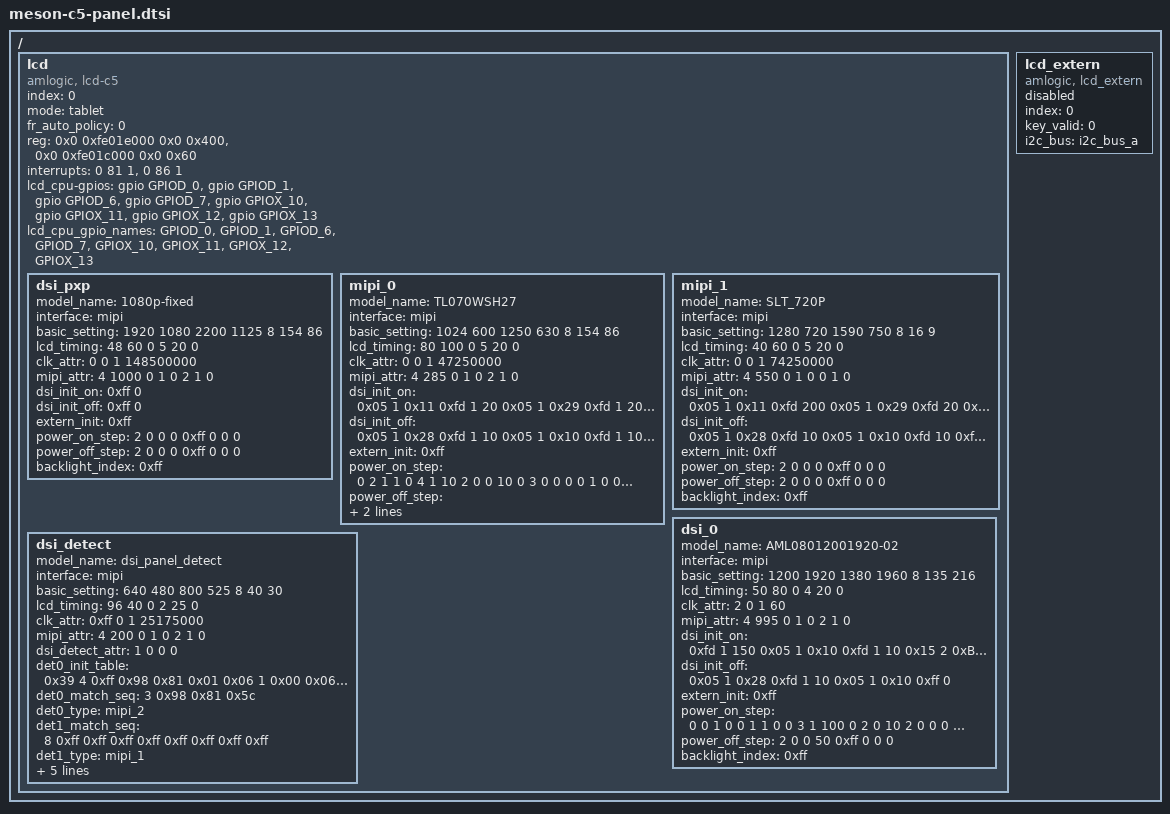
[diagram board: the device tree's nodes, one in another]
// SPDX-License-Identifier: (GPL-2.0+ OR MIT)
/*
 * Copyright (c) 2019 Amlogic, Inc. All rights reserved.
 */

/ {
	lcd:lcd {
		compatible = "amlogic, lcd-c5";
		status = "okay";
		index = <0>;
		mode = "tablet";
		// pxp = <10>;
		fr_auto_policy = <0>; /* 0=disable, 1=enable */
		// clocks = <&clkc CLKID_MIPI_DSI_MEAS>;
		// clock-names = "dsi_meas";
		reg = <0x0 0xfe01e000 0x0 0x400>, <0x0 0xfe01c000 0x0 0x60>; /*dsi host, dsi dphy*/
		interrupts = <0 81 1>, <0 86 1>;
		interrupt-names = "vsync","dsi_intr";
		/* power type:(0=cpu_gpio, 2=signal, 3=extern, 0xff=ending) */
		/* power index:(gpios_index, or extern_index, 0xff=invalid) */
		/* power value:(0=output low, 1=output high, 2=input) */
		/* power delay:(unit in ms) */

		lcd_cpu-gpios = <&gpio GPIOD_0 GPIO_ACTIVE_HIGH>, <&gpio GPIOD_1 GPIO_ACTIVE_HIGH>,
				<&gpio GPIOD_6 GPIO_ACTIVE_HIGH>, <&gpio GPIOD_7 GPIO_ACTIVE_HIGH>,
				<&gpio GPIOX_10 GPIO_ACTIVE_HIGH>,
				<&gpio GPIOX_11 GPIO_ACTIVE_HIGH>,
				<&gpio GPIOX_12 GPIO_ACTIVE_HIGH>,
				<&gpio GPIOX_13 GPIO_ACTIVE_HIGH>;
		lcd_cpu_gpio_names = "GPIOD_0", "GPIOD_1","GPIOD_6","GPIOD_7",
				"GPIOX_10","GPIOX_11","GPIOX_12","GPIOX_13";

		dsi_pxp{
			model_name = "1080p-fixed";
			interface = "mipi";
			basic_setting = <1920 1080 /*h_active, v_active*/
				2200 1125 /*h_period, v_period*/
				8 /*lcd_bits*/
				154 86>; /*screen_widht, screen_height*/
			lcd_timing = <48 60 0 /*hs_width, hs_bp, hs_pol*/
				5 20 0>; /*vs_width, vs_bp, vs_pol*/
			clk_attr = <0 /*fr_adj_type(0=clk, 1=htotal, 2=vtotal)*/
				0 /*clk_ss_level */
				1 /*clk_auto_generate*/
				148500000>; /*pixel_clk(unit in Hz)*/
			mipi_attr = <
				4   /*lane_num*/
				1000 /*bit_rate_max(MHz)*/
				0   /*unused*/
				1   /*operation_mode_init(0=video, 1=command)*/
				0   /*operation_mode_display(0=video, 1=command)*/
				2   /*video_mode_type: 0=sync_pulse,1=sync_event,2=burst)*/
				1   /*clk_always_hs(0=disable,1=enable)*/
				0>; /*unused*/
			/* dsi_init: data_type, num, data... */
			dsi_init_on = <
				0xff 0>; /*ending*/
			dsi_init_off = <
				0xff 0>; /*ending*/
			extern_init = <0xff>; /*0xff for invalid*/

			/* power step: type, index, value, delay(ms) */
			power_on_step = <
				2 0 0 0
				0xff 0 0 0>; /*ending*/
			power_off_step = <
				2 0 0 0
				0xff 0 0 0>; /*ending*/
			backlight_index = <0xff>;
		};

		mipi_0{
			model_name = "TL070WSH27";
			interface = "mipi";
			basic_setting = <1024 600 /*h_active, v_active*/
				1250 630 /*h_period, v_period*/
				8 /*lcd_bits*/
				154 86>; /*screen_widht, screen_height*/
			lcd_timing = <80 100 0 /*hs_width, hs_bp, hs_pol*/
				5 20 0>; /*vs_width, vs_bp, vs_pol*/
			clk_attr = <0 /*fr_adj_type(0=clk, 1=htotal, 2=vtotal)*/
				0 /*clk_ss_level */
				1 /*clk_auto_generate*/
				47250000>; /*pixel_clk(unit in Hz)*/
			mipi_attr = <
				4   /*lane_num*/
				285 /*bit_rate_max(MHz)*/
				0   /*unused*/
				1   /*operation_mode_init(0=video, 1=command)*/
				0   /*operation_mode_display(0=video, 1=command)*/
				2   /*video_mode_type: 0=sync_pulse,1=sync_event,2=burst)*/
				1   /*clk_always_hs(0=disable,1=enable)*/
				0>; /*unused*/
			/* dsi_init: data_type, num, data... */
			dsi_init_on = <
				0x05 1 0x11
				0xfd 1 20 /*delay(ms)*/
				0x05 1 0x29
				0xfd 1 20 /*delay(ms)*/
				0xff 0>; /*ending*/
			dsi_init_off = <0x05 1 0x28
				0xfd 1 10 /*delay(ms)*/
				0x05 1 0x10
				0xfd 1 10 /*delay(ms)*/
				0xff 0>; /*ending*/
			extern_init = <0xff>; /*0xff for invalid*/

			/* power step: type, index, value, delay(ms) */
			power_on_step = <
				0 2 1 1 /* GPIOD_6 3v3 */
				0 4 1 10 /* GPIOX_10 rst */
				2 0 0 10
				0 3 0 0 /* GPIOD_7 bl_pwm */
				0 0 1 0 /* GPIOD_0 bl_en */
				0xff 0 0 0>; /*ending*/
			power_off_step = <
				0 3 1 100 /* GPIOD_7 bl_pwm */
				0 0 0 0 /* GPIOD_0 bl_en */
				2 0 0 10
				0 2 0 0 /* GPIOD_6 3v3 */
				0 4 0 10 /* GPIOX_10 rst */
				0xff 0 0 0>; /*ending*/
			backlight_index = <0xff>;
		};
		mipi_1{
			model_name = "SLT_720P";
			interface = "mipi";
			/*h_active, v_active, h_period, v_period, color_bit, width, height*/
			basic_setting = <1280 720 1590 750 8 16 9>;
			/*hs_width, hs_bp, hs_pol, vs_width, vs_bp, vs_pol*/
			lcd_timing = <40 60 0 5 20 0>;
			clk_attr = <0 0 1 74250000>;
			/* <lane, bit_rate, /, mode_init(0=video,1=cmd), mode_disp(0=video,1=cmd)*/
			/* video_mode(0=sync_pulse,1=sync_event,2=burst), clk_hs, />*/
			mipi_attr = <4 550 0 1 0 0 1 0>;
			dsi_init_on = <
				0x05 1 0x11
				0xfd 200
				0x05 1 0x29
				0xfd 20
				0xff 0xff>; /* ending flag */
			dsi_init_off = <
				0x05 1 0x28
				0xfd 10
				0x05 1 0x10
				0xfd 10
				0xff 0xff>; /* ending flag */
			/* extern_init: 0xff for invalid */
			extern_init = <0xff>;
			/* power step: type,index,value,delay(ms) */
			power_on_step = <
				2 0 0 0
				0xff 0 0 0>;
			power_off_step = <
				2 0 0 0
				0xff 0 0 0>;
			backlight_index = <0xff>;
		};

		dsi_0{
			model_name = "AML08012001920-02";
			interface = "mipi";
			/*h_active, v_active, h_period, v_period, color_bit, width, height*/
			basic_setting = <1200 1920 1380 1960 8 135 216>;
			/*hs_width, hs_bp, hs_pol, vs_width, vs_bp, vs_pol*/
			lcd_timing = <50 80 0 4 20 0>;
			clk_attr = <2 0 1 60>;
			/* <lane, bit_rate, /, mode_init(0=video,1=cmd), mode_disp(0=video,1=cmd)*/
			/* video_mode(0=sync_pulse,1=sync_event,2=burst), clk_hs, />*/
			mipi_attr = <4 995 0 1 0 2 1 0>;
			/* dsi_init: data_type, num, data... */
			dsi_init_on = <
				0xfd 1 150
				0x05 1 0x10
				0xfd 1 10
				0x15 2 0xB0 0x05 0x15 2 0xB3 0x52 0x15 2 0xB0 0x01 0x15 2 0xC8 0x00
				0x15 2 0xC9 0x00 0x15 2 0xCC 0x26 0x15 2 0xCD 0x26 0x15 2 0xDC 0x00
				0x15 2 0xDD 0x00 0x15 2 0xE0 0x26 0x15 2 0xE1 0x26 0x15 2 0xB0 0x03
				0x15 2 0xC3 0x2A 0x15 2 0xE7 0x2A 0x15 2 0xC5 0x2A 0x15 2 0xDE 0x2A
				0x15 2 0xB0 0x00 0x15 2 0xB6 0x03 0x15 2 0xBA 0x87 0x15 2 0xBD 0x78
				0x15 2 0xBF 0x15 0x15 2 0xC0 0x12 0x15 2 0xC2 0x0C 0x15 2 0xC3 0x02
				0x15 2 0xC4 0x0C 0x15 2 0xC5 0x02 0x15 2 0xB0 0x06 0x15 2 0xC0 0xA5
				0x15 2 0xD5 0x20 0x15 2 0xC0 0x00
				0x15 2 0xB0 0x02 /* page2 */
				0x15 2 0xC0 0x00 0x15 2 0xC1 0x02 0x15 2 0xC2 0x06 0x15 2 0xC3 0x16
				0x15 2 0xC4 0x0E 0x15 2 0xC5 0x18 0x15 2 0xC6 0x26 0x15 2 0xC7 0x32
				0x15 2 0xC8 0x3F 0x15 2 0xC9 0x3F 0x15 2 0xCA 0x3F 0x15 2 0xCB 0x3F
				0x15 2 0xCC 0x3D 0x15 2 0xCD 0x2F 0x15 2 0xCE 0x2F 0x15 2 0xCF 0x2F
				0x15 2 0xD0 0x07 0x15 2 0xD2 0x00 0x15 2 0xD3 0x02 0x15 2 0xD4 0x06
				0x15 2 0xD5 0x12 0x15 2 0xD6 0x0A 0x15 2 0xD7 0x14 0x15 2 0xD8 0x22
				0x15 2 0xD9 0x2E 0x15 2 0xDA 0x3D 0x15 2 0xDB 0x3F 0x15 2 0xDC 0x3F
				0x15 2 0xDD 0x3F 0x15 2 0xDE 0x3D 0x15 2 0xDF 0x2F 0x15 2 0xE0 0x2F
				0x15 2 0xE1 0x2F 0x15 2 0xE2 0x07
				0x15 2 0xB0 0x07 /* page7 */
				0x15 2 0xB1 0x00 0x15 2 0xB2 0x19 0x15 2 0xB3 0x31 0x15 2 0xB4 0x5A
				0x15 2 0xB5 0x7C 0x15 2 0xB6 0x9C 0x15 2 0xB7 0xD3 0x15 2 0xB8 0x0E
				0x15 2 0xB9 0x7D 0x15 2 0xBA 0xE0 0x15 2 0xBB 0x7A 0x15 2 0xBC 0xE6
				0x15 2 0xBD 0xE9 0x15 2 0xBE 0x41 0x15 2 0xBF 0x91 0x15 2 0xC0 0xB0
				0x15 2 0xC1 0xCF 0x15 2 0xC2 0xDC 0x15 2 0xC3 0xE9 0x15 2 0xC4 0xEF
				0x15 2 0xC5 0xF5 0x15 2 0xC6 0xFA 0x15 2 0xC7 0xFB 0x15 2 0xC8 0xFC
				0x15 2 0xC9 0x00 0x15 2 0xCA 0x01 0x15 2 0xCB 0x5A 0x15 2 0xCC 0xBF
				0x15 2 0xCD 0xFF 0x15 2 0xCE 0xFF
				0x15 2 0xB0 0x08 /* page8 */
				0x15 2 0xB1 0x00 0x15 2 0xB2 0x19 0x15 2 0xB3 0x31 0x15 2 0xB4 0x5A
				0x15 2 0xB5 0x7C 0x15 2 0xB6 0x9C 0x15 2 0xB7 0xD3 0x15 2 0xB8 0x0E
				0x15 2 0xB9 0x7D 0x15 2 0xBA 0xE0 0x15 2 0xBB 0x7A 0x15 2 0xBC 0xE6
				0x15 2 0xBD 0xE9 0x15 2 0xBE 0x41 0x15 2 0xBF 0x91 0x15 2 0xC0 0xB0
				0x15 2 0xC1 0xCF 0x15 2 0xC2 0xDC 0x15 2 0xC3 0xE9 0x15 2 0xC4 0xEF
				0x15 2 0xC5 0xF5 0x15 2 0xC6 0xFA 0x15 2 0xC7 0xFB 0x15 2 0xC8 0xFC
				0x15 2 0xC9 0x00 0x15 2 0xCA 0x01 0x15 2 0xCB 0x5A 0x15 2 0xCC 0xBF
				0x15 2 0xCD 0xFF 0x15 2 0xCE 0xFF
				0x15 2 0xB0 0x09 /* page9 */
				0x15 2 0xB1 0x00 0x15 2 0xB2 0x19 0x15 2 0xB3 0x31 0x15 2 0xB4 0x5A
				0x15 2 0xB5 0x7C 0x15 2 0xB6 0x9C 0x15 2 0xB7 0xD3 0x15 2 0xB8 0x0E
				0x15 2 0xB9 0x7D 0x15 2 0xBA 0xE0 0x15 2 0xBB 0x7A 0x15 2 0xBC 0xE6
				0x15 2 0xBD 0xE9 0x15 2 0xBE 0x41 0x15 2 0xBF 0x91 0x15 2 0xC0 0xB0
				0x15 2 0xC1 0xCF 0x15 2 0xC2 0xDC 0x15 2 0xC3 0xE9 0x15 2 0xC4 0xEF
				0x15 2 0xC5 0xF5 0x15 2 0xC6 0xFA 0x15 2 0xC7 0xFB 0x15 2 0xC8 0xFC
				0x15 2 0xC9 0x00 0x15 2 0xCA 0x01 0x15 2 0xCB 0x5A 0x15 2 0xCC 0xBF
				0x15 2 0xCD 0xFF 0x15 2 0xCE 0xFF
				0x15 2 0xB0 0x0A /* page10 */
				0x15 2 0xB1 0x00 0x15 2 0xB2 0x19 0x15 2 0xB3 0x31 0x15 2 0xB4 0x5A
				0x15 2 0xB5 0x7C 0x15 2 0xB6 0x9C 0x15 2 0xB7 0xD3 0x15 2 0xB8 0x0E
				0x15 2 0xB9 0x7D 0x15 2 0xBA 0xE0 0x15 2 0xBB 0x7A 0x15 2 0xBC 0xE6
				0x15 2 0xBD 0xE9 0x15 2 0xBE 0x41 0x15 2 0xBF 0x91 0x15 2 0xC0 0xB0
				0x15 2 0xC1 0xCF 0x15 2 0xC2 0xDC 0x15 2 0xC3 0xE9 0x15 2 0xC4 0xEF
				0x15 2 0xC5 0xF5 0x15 2 0xC6 0xFA 0x15 2 0xC7 0xFC 0x15 2 0xC8 0xFC
				0x15 2 0xC9 0x00 0x15 2 0xCA 0x01 0x15 2 0xCB 0x5A 0x15 2 0xCC 0xBF
				0x15 2 0xCD 0xFF 0x15 2 0xCE 0xFF
				0x15 2 0xB0 0x0B /* page11 */
				0x15 2 0xB1 0x00 0x15 2 0xB2 0x19 0x15 2 0xB3 0x31 0x15 2 0xB4 0x5A
				0x15 2 0xB5 0x7C 0x15 2 0xB6 0x9C 0x15 2 0xB7 0xD3 0x15 2 0xB8 0x0E
				0x15 2 0xB9 0x7D 0x15 2 0xBA 0xE0 0x15 2 0xBB 0x7A 0x15 2 0xBC 0xE6
				0x15 2 0xBD 0xE9 0x15 2 0xBE 0x41 0x15 2 0xBF 0x91 0x15 2 0xC0 0xB0
				0x15 2 0xC1 0xCF 0x15 2 0xC2 0xDC 0x15 2 0xC3 0xE9 0x15 2 0xC4 0xEF
				0x15 2 0xC5 0xF5 0x15 2 0xC6 0xFA 0x15 2 0xC7 0xFC 0x15 2 0xC8 0xFC
				0x15 2 0xC9 0x00 0x15 2 0xCA 0x01 0x15 2 0xCB 0x5A 0x15 2 0xCC 0xBF
				0x15 2 0xCD 0xFF 0x15 2 0xCE 0xFF
				0x15 2 0xB0 0x0C /* page12 */
				0x15 2 0xB1 0x00 0x15 2 0xB2 0x19 0x15 2 0xB3 0x31 0x15 2 0xB4 0x5A
				0x15 2 0xB5 0x7C 0x15 2 0xB6 0x9C 0x15 2 0xB7 0xD3 0x15 2 0xB8 0x0E
				0x15 2 0xB9 0x7D 0x15 2 0xBA 0xE0 0x15 2 0xBB 0x7A 0x15 2 0xBC 0xE6
				0x15 2 0xBD 0xE9 0x15 2 0xBE 0x41 0x15 2 0xBF 0x91 0x15 2 0xC0 0xB0
				0x15 2 0xC1 0xCF 0x15 2 0xC2 0xDC 0x15 2 0xC3 0xE9 0x15 2 0xC4 0xEF
				0x15 2 0xC5 0xF5 0x15 2 0xC6 0xFA 0x15 2 0xC7 0xFC 0x15 2 0xC8 0xFC
				0x15 2 0xC9 0x00 0x15 2 0xCA 0x01 0x15 2 0xCB 0x5A 0x15 2 0xCC 0xBF
				0x15 2 0xCD 0xFF 0x15 2 0xCE 0xFF
				0xfd 1 10
				0x05 1 0x11
				0xfd 1 100
				0x05 1 0x29
				0xfd 1 50
				0xff 0>; /*ending*/
			dsi_init_off = <
				0x05 1 0x28
				0xfd 1 10
				0x05 1 0x10
				0xff 0>;
			extern_init = <0xff>; /*0xff for invalid*/

			/* power step: type, index, value, delay(ms) */
			power_on_step = <
				0 0 1 0
				0 1 1 0
				0 3 1 100
				0 2 0 10
				2 0 0 0
				0xff 0 0 0>; /*ending*/
			power_off_step = <
				2 0 0 50
				0xff 0 0 0>; /*ending*/
			backlight_index = <0xff>;
		};

		dsi_detect{
			model_name = "dsi_panel_detect";
			interface = "mipi";

			//<H_active, V_active, H_period, V_period, lcd_bits, width, height>
			basic_setting = <640 480 800 525 8 40 30>;
			//<HSync, HS_backporch, HS_pol, VSync, VS_backporch, VS_pol>
			lcd_timing = <96 40 0 2 25 0>;
			//<fr_adj_type clk_ss clk_auto_generate PixelClk>
			clk_attr = <0xff 0 1 25175000>;
			//<lane_num bit_rate \ mode_init mode_display video_mode clk_always_hs \>
			mipi_attr = <4 200 0 1 0 2 1 0>;

			//<stored2env \ \ \>
			dsi_detect_attr = <1 0 0 0>;
			/* dsi_init: data_type, num, data... */
			det0_init_table = <
				0x39 4 0xff 0x98 0x81 0x01
				0x06 1 0x00 0x06 1 0x01 0x06 1 0x02
				0xff 0>;
			det0_match_seq = <3 0x98 0x81 0x5c>;
			det0_type = "mipi_2";

			det1_match_seq = <8 0xff 0xff 0xff 0xff 0xff 0xff 0xff 0xff>;
			det1_type = "mipi_1";

			fallback_type = "mipi_0";

			/* power step: type, index, value, delay(ms) */
			power_on_step = <
				0 0 1 10 /*vcc en*/
				0 1 1 1 /*rst high*/
				0 3 1 30 /*3v3 high*/
				0 1 0 10 /*rst low*/
				0 1 1 20 /*rst high*/
				2 0 0 0
				0 0 0 1
				0 1 0 1 /*rst low*/
				0 3 0 1 /*3v3 low*/
				0xff 0 0 0>; /*ending*/
			power_off_step = <0xff 0 0 0>; /*ending*/
			backlight_index = <0xff>;
		};
		/*
		 *ports {
		 *	port {
		 *		#address-cells = <1>;
		 *		#size-cells = <0>;
		 *		lcd0_to_drm: endpoint@0 {
		 *			reg = <0>;
		 *			remote-endpoint = <0>;
		 *		};
		 *	};
		 *};
		 */
	};
	lcd_extern{
		compatible = "amlogic, lcd_extern";
		status = "disabled";
		index = <0>;
		key_valid = <0>;
		i2c_bus = "i2c_bus_a";
	};
}; /* end of / */

//&pwm_c {
//	status = "okay";
//};
